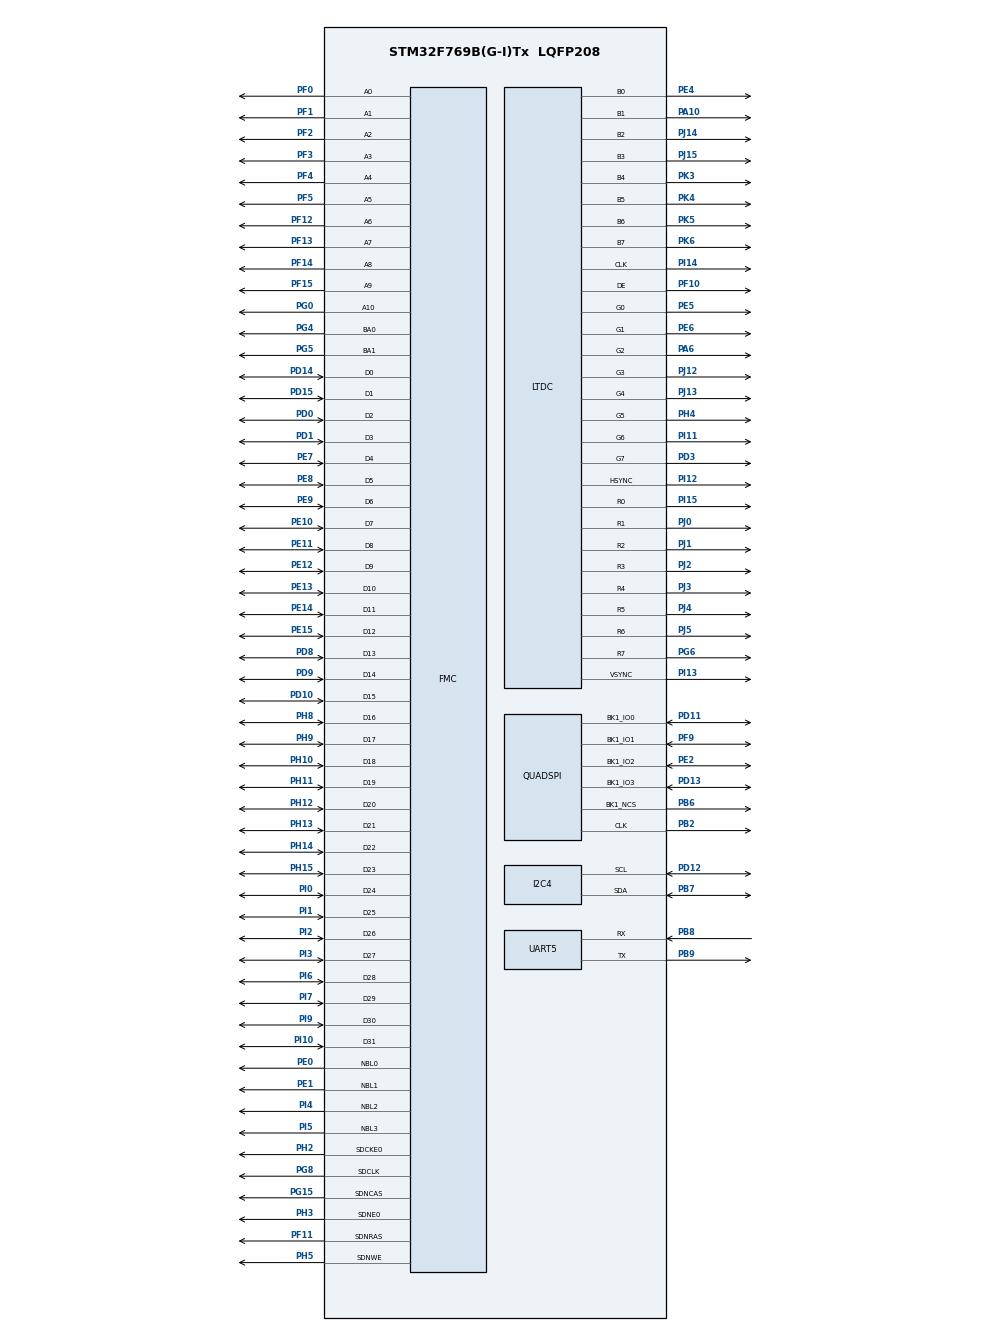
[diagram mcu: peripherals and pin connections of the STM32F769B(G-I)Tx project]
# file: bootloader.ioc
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FMC.ExitSelfRefreshDelay1=6
FMC.LoadToActiveDelay1=2
FMC.RCDDelay1=2
FMC.RPDelay1=2
FMC.RPDelay2=2
FMC.RowCycleDelay1=6
FMC.RowCycleDelay2=6
FMC.SelfRefreshTime1=4
FMC.WriteRecoveryTime1=2
LTDC.ActiveW=800
LTDC.Alpha_L0=255
LTDC.HBP=13
LTDC.HFP=32
LTDC.HSync=41
LTDC.ImageHeight_L0=480
LTDC.ImageWidth_L0=800
LTDC.Layers=0
LTDC.PixelFormat_L0=LTDC_PIXEL_FORMAT_RGB565
LTDC.VSync=10
LTDC.WindowX1_L0=800
LTDC.WindowY1_L0=480
Mcu.Family=STM32F7
Mcu.Name=STM32F769B(G-I)Tx
Mcu.Package=LQFP208
NVIC.I2C4_ER_IRQn=true\:0\:0\:false\:false\:true\:true\:true
NVIC.I2C4_EV_IRQn=true\:0\:0\:false\:false\:true\:true\:true
NVIC.PriorityGroup=NVIC_PRIORITYGROUP_4
PA10.Mode=RGB888
PA10.Signal=LTDC_B1
PA6.Mode=RGB888
PA6.Signal=LTDC_G2
PB2.Mode=Single Bank 1
PB2.Signal=QUADSPI_CLK
PB6.Mode=Single Bank 1
PB6.Signal=QUADSPI_BK1_NCS
PB7.Mode=I2C
PB7.Signal=I2C4_SDA
PB8.Mode=Asynchronous
PB8.Signal=UART5_RX
PB9.Mode=Asynchronous
PB9.Signal=UART5_TX
PD0.Signal=FMC_D2_DA2
PD1.Signal=FMC_D3_DA3
PD10.Signal=FMC_D15_DA15
PD11.Mode=Single Bank 1
PD11.Signal=QUADSPI_BK1_IO0
PD12.Mode=I2C
PD12.Signal=I2C4_SCL
PD13.Mode=Single Bank 1
PD13.Signal=QUADSPI_BK1_IO3
PD14.Signal=FMC_D0_DA0
PD15.Signal=FMC_D1_DA1
PD3.Mode=RGB888
PD3.Signal=LTDC_G7
PD8.Signal=FMC_D13_DA13
PD9.Signal=FMC_D14_DA14
PE0.Signal=FMC_NBL0
PE1.Signal=FMC_NBL1
PE10.Signal=FMC_D7_DA7
PE11.Signal=FMC_D8_DA8
PE12.Signal=FMC_D9_DA9
PE13.Signal=FMC_D10_DA10
PE14.Signal=FMC_D11_DA11
PE15.Signal=FMC_D12_DA12
PE2.Mode=Single Bank 1
PE2.Signal=QUADSPI_BK1_IO2
PE4.Mode=RGB888
PE4.Signal=LTDC_B0
PE5.Mode=RGB888
PE5.Signal=LTDC_G0
PE6.Mode=RGB888
PE6.Signal=LTDC_G1
PE7.Signal=FMC_D4_DA4
PE8.Signal=FMC_D5_DA5
PE9.Signal=FMC_D6_DA6
PF0.Signal=FMC_A0
PF1.Signal=FMC_A1
PF10.Mode=RGB888
PF10.Signal=LTDC_DE
PF11.Signal=FMC_SDNRAS
PF12.Signal=FMC_A6
PF13.Signal=FMC_A7
PF14.Signal=FMC_A8
PF15.Signal=FMC_A9
PF2.Signal=FMC_A2
PF3.Signal=FMC_A3
PF4.Signal=FMC_A4
PF5.Signal=FMC_A5
PF9.Mode=Single Bank 1
PF9.Signal=QUADSPI_BK1_IO1
PG0.Signal=FMC_A10
PG15.Signal=FMC_SDNCAS
PG4.Signal=FMC_A14_BA0
PG5.Signal=FMC_A15_BA1
PG6.Mode=RGB888
PG6.Signal=LTDC_R7
PG8.Signal=FMC_SDCLK
PH10.Signal=FMC_D18
PH11.Signal=FMC_D19
PH12.Signal=FMC_D20
PH13.Signal=FMC_D21
PH14.Signal=FMC_D22
PH15.Signal=FMC_D23
PH2.Mode=SdramChipSelect1_1
PH2.Signal=FMC_SDCKE0
PH3.Mode=SdramChipSelect1_1
PH3.Signal=FMC_SDNE0
PH4.Mode=RGB888
PH4.Signal=LTDC_G5
PH5.Signal=FMC_SDNWE
PH8.Signal=FMC_D16
PH9.Signal=FMC_D17
PI0.Signal=FMC_D24
PI1.Signal=FMC_D25
PI10.Signal=FMC_D31
PI11.Mode=RGB888
PI11.Signal=LTDC_G6
PI12.Mode=RGB888
PI12.Signal=LTDC_HSYNC
PI13.Mode=RGB888
PI13.Signal=LTDC_VSYNC
PI14.Mode=RGB888
PI14.Signal=LTDC_CLK
PI15.Mode=RGB888
PI15.Signal=LTDC_R0
PI2.Signal=FMC_D26
PI3.Signal=FMC_D27
PI4.Signal=FMC_NBL2
PI5.Signal=FMC_NBL3
PI6.Signal=FMC_D28
PI7.Signal=FMC_D29
PI9.Signal=FMC_D30
PJ0.Mode=RGB888
PJ0.Signal=LTDC_R1
PJ1.Mode=RGB888
PJ1.Signal=LTDC_R2
PJ12.Mode=RGB888
PJ12.Signal=LTDC_G3
PJ13.Mode=RGB888
PJ13.Signal=LTDC_G4
PJ14.Mode=RGB888
PJ14.Signal=LTDC_B2
PJ15.Mode=RGB888
PJ15.Signal=LTDC_B3
PJ2.Mode=RGB888
PJ2.Signal=LTDC_R3
PJ3.Mode=RGB888
PJ3.Signal=LTDC_R4
PJ4.Mode=RGB888
PJ4.Signal=LTDC_R5
PJ5.Mode=RGB888
PJ5.Signal=LTDC_R6
PK3.Mode=RGB888
PK3.Signal=LTDC_B4
PK4.Mode=RGB888
PK4.Signal=LTDC_B5
PK5.Mode=RGB888
PK5.Signal=LTDC_B6
PK6.Mode=RGB888
PK6.Signal=LTDC_B7
ProjectManager.HeapSize=0x200
ProjectManager.StackSize=0x400
ProjectManager.TargetToolchain=Makefile
QUADSPI.ClockPrescaler=1
QUADSPI.FifoThreshold=16
QUADSPI.FlashSize=31
QUADSPI.SampleShifting=QSPI_SAMPLE_SHIFTING_HALFCYCLE
RCC.HSE_VALUE=25000000
RCC.HSI_VALUE=16000000
RCC.LSE_VALUE=32768
RCC.USBFreq_Value=96000000
RCC.VCOOutputFreq_Value=192000000
SH.FMC_A0.0=FMC_A0,11b-sda1
SH.FMC_A1.0=FMC_A1,11b-sda1
SH.FMC_A10.0=FMC_A10,11b-sda1
SH.FMC_A14_BA0.0=FMC_BA0,FourSdramBanks1
SH.FMC_A15_BA1.0=FMC_BA1,FourSdramBanks1
SH.FMC_A2.0=FMC_A2,11b-sda1
SH.FMC_A3.0=FMC_A3,11b-sda1
SH.FMC_A4.0=FMC_A4,11b-sda1
SH.FMC_A5.0=FMC_A5,11b-sda1
SH.FMC_A6.0=FMC_A6,11b-sda1
SH.FMC_A7.0=FMC_A7,11b-sda1
SH.FMC_A8.0=FMC_A8,11b-sda1
SH.FMC_A9.0=FMC_A9,11b-sda1
SH.FMC_D0_DA0.0=FMC_D0,sd-32b-d1
SH.FMC_D10_DA10.0=FMC_D10,sd-32b-d1
SH.FMC_D11_DA11.0=FMC_D11,sd-32b-d1
SH.FMC_D12_DA12.0=FMC_D12,sd-32b-d1
SH.FMC_D13_DA13.0=FMC_D13,sd-32b-d1
SH.FMC_D14_DA14.0=FMC_D14,sd-32b-d1
SH.FMC_D15_DA15.0=FMC_D15,sd-32b-d1
SH.FMC_D16.0=FMC_D16,sd-32b-d1
SH.FMC_D17.0=FMC_D17,sd-32b-d1
SH.FMC_D18.0=FMC_D18,sd-32b-d1
SH.FMC_D19.0=FMC_D19,sd-32b-d1
SH.FMC_D1_DA1.0=FMC_D1,sd-32b-d1
SH.FMC_D20.0=FMC_D20,sd-32b-d1
SH.FMC_D21.0=FMC_D21,sd-32b-d1
SH.FMC_D22.0=FMC_D22,sd-32b-d1
SH.FMC_D23.0=FMC_D23,sd-32b-d1
SH.FMC_D24.0=FMC_D24,sd-32b-d1
SH.FMC_D25.0=FMC_D25,sd-32b-d1
SH.FMC_D26.0=FMC_D26,sd-32b-d1
SH.FMC_D27.0=FMC_D27,sd-32b-d1
SH.FMC_D28.0=FMC_D28,sd-32b-d1
SH.FMC_D29.0=FMC_D29,sd-32b-d1
SH.FMC_D2_DA2.0=FMC_D2,sd-32b-d1
SH.FMC_D30.0=FMC_D30,sd-32b-d1
SH.FMC_D31.0=FMC_D31,sd-32b-d1
SH.FMC_D3_DA3.0=FMC_D3,sd-32b-d1
SH.FMC_D4_DA4.0=FMC_D4,sd-32b-d1
SH.FMC_D5_DA5.0=FMC_D5,sd-32b-d1
SH.FMC_D6_DA6.0=FMC_D6,sd-32b-d1
SH.FMC_D7_DA7.0=FMC_D7,sd-32b-d1
SH.FMC_D8_DA8.0=FMC_D8,sd-32b-d1
SH.FMC_D9_DA9.0=FMC_D9,sd-32b-d1
SH.FMC_NBL0.0=FMC_NBL0,Sd4ByteEnable1
SH.FMC_NBL1.0=FMC_NBL1,Sd4ByteEnable1
SH.FMC_NBL2.0=FMC_NBL2,Sd4ByteEnable1
SH.FMC_NBL3.0=FMC_NBL3,Sd4ByteEnable1
SH.FMC_SDCLK.0=FMC_SDCLK,11b-sda1
SH.FMC_SDNCAS.0=FMC_SDNCAS,11b-sda1
SH.FMC_SDNRAS.0=FMC_SDNRAS,11b-sda1
SH.FMC_SDNWE.0=FMC_SDNWE,11b-sda1
board=custom

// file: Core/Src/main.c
/* USER CODE BEGIN Header */
/**
  ******************************************************************************
  * @file           : main.c
  * @brief          : Main program body
  ******************************************************************************
  * @attention
  *
  * <h2><center>&copy; Copyright (c) 2021 STMicroelectronics.
  * All rights reserved.</center></h2>
  *
  * This software component is licensed by ST under BSD 3-Clause license,
  * the "License"; You may not use this file except in compliance with the
  * License. You may obtain a copy of the License at:
  *                        opensource.org/licenses/BSD-3-Clause
  *
  ******************************************************************************
  */
/* USER CODE END Header */
#include "main.h"

/* USER CODE BEGIN Includes */
#include <stdio.h>
#include "lcd.h"
#include "sdram.h"
#include "ts.h"
/* USER CODE END Includes */

I2C_HandleTypeDef hi2c4;

LTDC_HandleTypeDef hltdc;

QSPI_HandleTypeDef hqspi;

UART_HandleTypeDef huart5;

SDRAM_HandleTypeDef hsdram1;

void SystemClock_Config(void);
static void MX_GPIO_Init(void);
static void MX_I2C4_Init(void);
static void MX_LTDC_Init(void);
static void MX_QUADSPI_Init(void);
static void MX_UART5_Init(void);
static void MX_FMC_Init(void);

int main(void)
{

  /* MCU Configuration--------------------------------------------------------*/

  /* Reset of all peripherals, Initializes the Flash interface and the Systick. */
  HAL_Init();

  /* Configure the system clock */
  SystemClock_Config();

  /* Initialize all configured peripherals */
  MX_GPIO_Init();
  MX_I2C4_Init();
  MX_LTDC_Init();
  MX_QUADSPI_Init();
  MX_UART5_Init();
  MX_FMC_Init();
  /* USER CODE BEGIN 2 */
  printf("LCD Demo\r\n");
  sdram_setup();
  lcd_fill_buff();
  HAL_Delay(1000);//sample delay
  config_lcd_layer();
  BSP_LCD_DisplayStringAt(0, 0, (uint8_t*)"LCD DEMO", CENTER_MODE);

  printf("LCD init done\r\n");

  touch_init();

  /* USER CODE END 2 */

  /* Infinite loop */
  while (1)
  {
    //touch_detect();
  }
}

void SystemClock_Config(void)
{
  RCC_OscInitTypeDef RCC_OscInitStruct = {0};
  RCC_ClkInitTypeDef RCC_ClkInitStruct = {0};
  RCC_PeriphCLKInitTypeDef PeriphClkInitStruct = {0};

  /** Macro to configure the PLL multiplication factor
  */
  __HAL_RCC_PLL_PLLM_CONFIG(16);
  /** Macro to configure the PLL clock source
  */
  __HAL_RCC_PLL_PLLSOURCE_CONFIG(RCC_PLLSOURCE_HSI);
  /** Configure the main internal regulator output voltage
  */
  __HAL_RCC_PWR_CLK_ENABLE();
  __HAL_PWR_VOLTAGESCALING_CONFIG(PWR_REGULATOR_VOLTAGE_SCALE3);
  /** Initializes the RCC Oscillators according to the specified parameters
  * in the RCC_OscInitTypeDef structure.
  */
  RCC_OscInitStruct.OscillatorType = RCC_OSCILLATORTYPE_HSI;
  RCC_OscInitStruct.HSIState = RCC_HSI_ON;
  RCC_OscInitStruct.HSICalibrationValue = RCC_HSICALIBRATION_DEFAULT;
  RCC_OscInitStruct.PLL.PLLState = RCC_PLL_NONE;
  RCC_OscInitStruct.PLL.PLLSource = RCC_PLLSOURCE_HSI;
  RCC_OscInitStruct.PLL.PLLM = 16;
  if (HAL_RCC_OscConfig(&RCC_OscInitStruct) != HAL_OK)
  {
    Error_Handler();
  }
  /** Initializes the CPU, AHB and APB buses clocks
  */
  RCC_ClkInitStruct.ClockType = RCC_CLOCKTYPE_HCLK|RCC_CLOCKTYPE_SYSCLK
                              |RCC_CLOCKTYPE_PCLK1|RCC_CLOCKTYPE_PCLK2;
  RCC_ClkInitStruct.SYSCLKSource = RCC_SYSCLKSOURCE_HSI;
  RCC_ClkInitStruct.AHBCLKDivider = RCC_SYSCLK_DIV1;
  RCC_ClkInitStruct.APB1CLKDivider = RCC_HCLK_DIV1;
  RCC_ClkInitStruct.APB2CLKDivider = RCC_HCLK_DIV1;

  if (HAL_RCC_ClockConfig(&RCC_ClkInitStruct, FLASH_LATENCY_0) != HAL_OK)
  {
    Error_Handler();
  }
  PeriphClkInitStruct.PeriphClockSelection = RCC_PERIPHCLK_LTDC|RCC_PERIPHCLK_UART5
                              |RCC_PERIPHCLK_I2C4;
  PeriphClkInitStruct.PLLSAI.PLLSAIN = 192;
  PeriphClkInitStruct.PLLSAI.PLLSAIR = 2;
  PeriphClkInitStruct.PLLSAI.PLLSAIQ = 2;
  PeriphClkInitStruct.PLLSAI.PLLSAIP = RCC_PLLSAIP_DIV2;
  PeriphClkInitStruct.PLLSAIDivQ = 1;
  PeriphClkInitStruct.PLLSAIDivR = RCC_PLLSAIDIVR_2;
  PeriphClkInitStruct.Uart5ClockSelection = RCC_UART5CLKSOURCE_PCLK1;
  PeriphClkInitStruct.I2c4ClockSelection = RCC_I2C4CLKSOURCE_PCLK1;
  if (HAL_RCCEx_PeriphCLKConfig(&PeriphClkInitStruct) != HAL_OK)
  {
    Error_Handler();
  }
}

static void MX_I2C4_Init(void)
{

  hi2c4.Instance = I2C4;
  hi2c4.Init.Timing = 0x00303D5B;
  hi2c4.Init.OwnAddress1 = 0;
  hi2c4.Init.AddressingMode = I2C_ADDRESSINGMODE_7BIT;
  hi2c4.Init.DualAddressMode = I2C_DUALADDRESS_DISABLE;
  hi2c4.Init.OwnAddress2 = 0;
  hi2c4.Init.OwnAddress2Masks = I2C_OA2_NOMASK;
  hi2c4.Init.GeneralCallMode = I2C_GENERALCALL_DISABLE;
  hi2c4.Init.NoStretchMode = I2C_NOSTRETCH_DISABLE;
  if (HAL_I2C_Init(&hi2c4) != HAL_OK)
  {
    Error_Handler();
  }
  /** Configure Analogue filter
  */
  if (HAL_I2CEx_ConfigAnalogFilter(&hi2c4, I2C_ANALOGFILTER_ENABLE) != HAL_OK)
  {
    Error_Handler();
  }
  /** Configure Digital filter
  */
  if (HAL_I2CEx_ConfigDigitalFilter(&hi2c4, 0) != HAL_OK)
  {
    Error_Handler();
  }

}

static void MX_LTDC_Init(void)
{

  LTDC_LayerCfgTypeDef pLayerCfg = {0};
  LTDC_LayerCfgTypeDef pLayerCfg1 = {0};

  hltdc.Instance = LTDC;
  hltdc.Init.HSPolarity = LTDC_HSPOLARITY_AL;
  hltdc.Init.VSPolarity = LTDC_VSPOLARITY_AL;
  hltdc.Init.DEPolarity = LTDC_DEPOLARITY_AL;
  hltdc.Init.PCPolarity = LTDC_PCPOLARITY_IPC;
  hltdc.Init.HorizontalSync = 40;
  hltdc.Init.VerticalSync = 9;
  hltdc.Init.AccumulatedHBP = 53;
  hltdc.Init.AccumulatedVBP = 11;
  hltdc.Init.AccumulatedActiveW = 853;
  hltdc.Init.AccumulatedActiveH = 491;
  hltdc.Init.TotalWidth = 885;
  hltdc.Init.TotalHeigh = 493;
  hltdc.Init.Backcolor.Blue = 0;
  hltdc.Init.Backcolor.Green = 0;
  hltdc.Init.Backcolor.Red = 0;
  if (HAL_LTDC_Init(&hltdc) != HAL_OK)
  {
    Error_Handler();
  }
  pLayerCfg.WindowX0 = 0;
  pLayerCfg.WindowX1 = 800;
  pLayerCfg.WindowY0 = 0;
  pLayerCfg.WindowY1 = 480;
  pLayerCfg.PixelFormat = LTDC_PIXEL_FORMAT_RGB565;
  pLayerCfg.Alpha = 255;
  pLayerCfg.Alpha0 = 0;
  pLayerCfg.BlendingFactor1 = LTDC_BLENDING_FACTOR1_CA;
  pLayerCfg.BlendingFactor2 = LTDC_BLENDING_FACTOR2_CA;
  pLayerCfg.FBStartAdress = 0;
  pLayerCfg.ImageWidth = 800;
  pLayerCfg.ImageHeight = 480;
  pLayerCfg.Backcolor.Blue = 0;
  pLayerCfg.Backcolor.Green = 0;
  pLayerCfg.Backcolor.Red = 0;
  if (HAL_LTDC_ConfigLayer(&hltdc, &pLayerCfg, 0) != HAL_OK)
  {
    Error_Handler();
  }
  pLayerCfg1.WindowX0 = 0;
  pLayerCfg1.WindowX1 = 0;
  pLayerCfg1.WindowY0 = 0;
  pLayerCfg1.WindowY1 = 0;
  pLayerCfg1.PixelFormat = LTDC_PIXEL_FORMAT_ARGB8888;
  pLayerCfg1.Alpha = 0;
  pLayerCfg1.Alpha0 = 0;
  pLayerCfg1.BlendingFactor1 = LTDC_BLENDING_FACTOR1_CA;
  pLayerCfg1.BlendingFactor2 = LTDC_BLENDING_FACTOR2_CA;
  pLayerCfg1.FBStartAdress = 0;
  pLayerCfg1.ImageWidth = 0;
  pLayerCfg1.ImageHeight = 0;
  pLayerCfg1.Backcolor.Blue = 0;
  pLayerCfg1.Backcolor.Green = 0;
  pLayerCfg1.Backcolor.Red = 0;
  if (HAL_LTDC_ConfigLayer(&hltdc, &pLayerCfg1, 1) != HAL_OK)
  {
    Error_Handler();
  }

}

static void MX_QUADSPI_Init(void)
{

  /* QUADSPI parameter configuration*/
  hqspi.Instance = QUADSPI;
  hqspi.Init.ClockPrescaler = 1;
  hqspi.Init.FifoThreshold = 16;
  hqspi.Init.SampleShifting = QSPI_SAMPLE_SHIFTING_HALFCYCLE;
  hqspi.Init.FlashSize = 31;
  hqspi.Init.ChipSelectHighTime = QSPI_CS_HIGH_TIME_1_CYCLE;
  hqspi.Init.ClockMode = QSPI_CLOCK_MODE_0;
  hqspi.Init.FlashID = QSPI_FLASH_ID_1;
  hqspi.Init.DualFlash = QSPI_DUALFLASH_DISABLE;
  if (HAL_QSPI_Init(&hqspi) != HAL_OK)
  {
    Error_Handler();
  }

}

static void MX_UART5_Init(void)
{

  huart5.Instance = UART5;
  huart5.Init.BaudRate = 115200;
  huart5.Init.WordLength = UART_WORDLENGTH_8B;
  huart5.Init.StopBits = UART_STOPBITS_1;
  huart5.Init.Parity = UART_PARITY_NONE;
  huart5.Init.Mode = UART_MODE_TX_RX;
  huart5.Init.HwFlowCtl = UART_HWCONTROL_NONE;
  huart5.Init.OverSampling = UART_OVERSAMPLING_16;
  huart5.Init.OneBitSampling = UART_ONE_BIT_SAMPLE_DISABLE;
  huart5.AdvancedInit.AdvFeatureInit = UART_ADVFEATURE_NO_INIT;
  if (HAL_UART_Init(&huart5) != HAL_OK)
  {
    Error_Handler();
  }

}

/* FMC initialization function */
static void MX_FMC_Init(void)
{

  FMC_SDRAM_TimingTypeDef SdramTiming = {0};

  /** Perform the SDRAM1 memory initialization sequence
  */
  hsdram1.Instance = FMC_SDRAM_DEVICE;
  /* hsdram1.Init */
  hsdram1.Init.SDBank = FMC_SDRAM_BANK1;
  hsdram1.Init.ColumnBitsNumber = FMC_SDRAM_COLUMN_BITS_NUM_8;
  hsdram1.Init.RowBitsNumber = FMC_SDRAM_ROW_BITS_NUM_11;
  hsdram1.Init.MemoryDataWidth = FMC_SDRAM_MEM_BUS_WIDTH_32;
  hsdram1.Init.InternalBankNumber = FMC_SDRAM_INTERN_BANKS_NUM_4;
  hsdram1.Init.CASLatency = FMC_SDRAM_CAS_LATENCY_1;
  hsdram1.Init.WriteProtection = FMC_SDRAM_WRITE_PROTECTION_DISABLE;
  hsdram1.Init.SDClockPeriod = FMC_SDRAM_CLOCK_DISABLE;
  hsdram1.Init.ReadBurst = FMC_SDRAM_RBURST_DISABLE;
  hsdram1.Init.ReadPipeDelay = FMC_SDRAM_RPIPE_DELAY_0;
  /* SdramTiming */
  SdramTiming.LoadToActiveDelay = 2;
  SdramTiming.ExitSelfRefreshDelay = 6;
  SdramTiming.SelfRefreshTime = 4;
  SdramTiming.RowCycleDelay = 6;
  SdramTiming.WriteRecoveryTime = 2;
  SdramTiming.RPDelay = 2;
  SdramTiming.RCDDelay = 2;

  if (HAL_SDRAM_Init(&hsdram1, &SdramTiming) != HAL_OK)
  {
    Error_Handler( );
  }

}

static void MX_GPIO_Init(void)
{

  /* GPIO Ports Clock Enable */
  __HAL_RCC_GPIOE_CLK_ENABLE();
  __HAL_RCC_GPIOI_CLK_ENABLE();
  __HAL_RCC_GPIOF_CLK_ENABLE();
  __HAL_RCC_GPIOH_CLK_ENABLE();
  __HAL_RCC_GPIOA_CLK_ENABLE();
  __HAL_RCC_GPIOB_CLK_ENABLE();
  __HAL_RCC_GPIOJ_CLK_ENABLE();
  __HAL_RCC_GPIOG_CLK_ENABLE();
  __HAL_RCC_GPIOD_CLK_ENABLE();
  __HAL_RCC_GPIOK_CLK_ENABLE();

}

void Error_Handler(void)
{
}

/************************ (C) COPYRIGHT STMicroelectronics *****END OF FILE****/
